# XHSC_HC32F420 register map
Vendor: XHSC Co.Ltd; Series: ARMCM4; File version: 1.2
CPU: CM4 r0p0, little endian, no MPU, no FPU, 3 interrupt priority bits
Registers are 32-bit, read-write, reset 0x0 unless marked. A register's access mark holds for its fields unless they carry their own. Offsets are from the block's base; [hi:lo] are bit positions; {n}, {i} and the like mark numbered series.

## CTRIM
Base 0x40008000
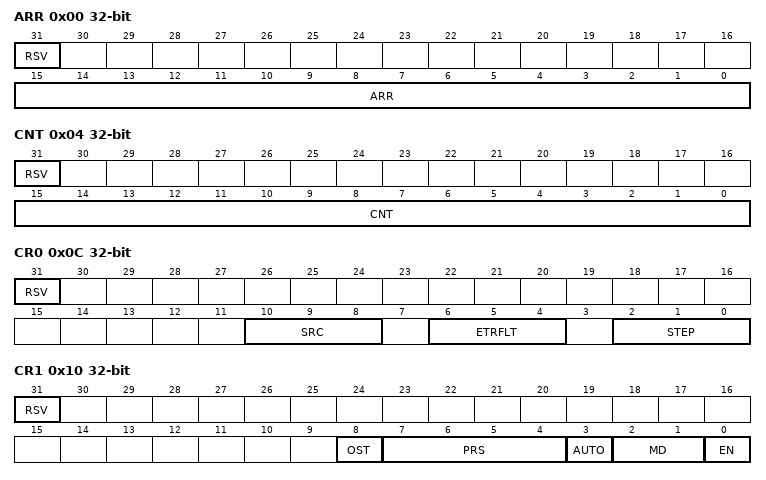
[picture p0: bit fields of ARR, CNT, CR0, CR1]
0x00 ARR (reset mask 0xFFFF)
  [31] RSV, [15:0] ARR
0x04 CNT ro (reset mask 0xFFFF)
  [31] RSV rw, [15:0] CNT rw
0x0C CR0 (reset mask 0xFFFF)
  [31] RSV, [10:8] SRC, [6:4] ETRFLT, [2:0] STEP
0x10 CR1 (reset mask 0xFFFF)
  [31] RSV, [8] OST, [7:4] PRS, [3] AUTO, [2:1] MD, [0] EN
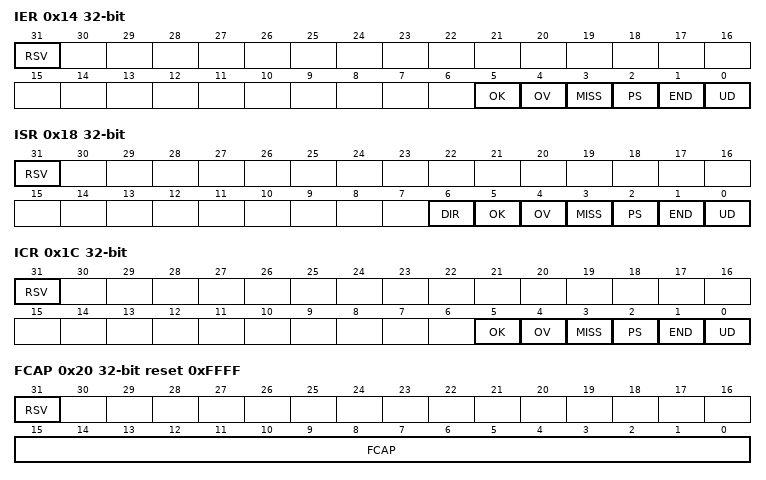
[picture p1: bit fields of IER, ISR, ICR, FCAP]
0x14 IER (reset mask 0xFF)
  [31] RSV, [5] OK, [4] OV, [3] MISS, [2] PS, [1] END, [0] UD
0x18 ISR ro (reset mask 0xFF)
  [31] RSV, [6] DIR, [5] OK, [4] OV, [3] MISS, [2] PS, [1] END, [0] UD
0x1C ICR (reset mask 0xFF)
  [31] RSV, [5] OK, [4] OV, [3] MISS, [2] PS, [1] END, [0] UD
0x20 FCAP ro reset 0xFFFF (reset mask 0xFFFF)
  [31] RSV, [15:0] FCAP
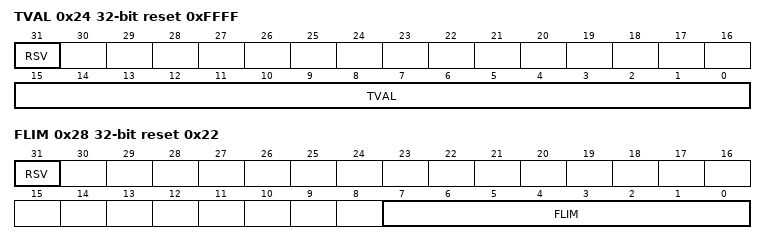
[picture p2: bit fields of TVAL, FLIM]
0x24 TVAL ro reset 0xFFFF (reset mask 0xFFFF)
  [31] RSV, [15:0] TVAL
0x28 FLIM reset 0x22 (reset mask 0xFF)
  [31] RSV, [7:0] FLIM

## DMAC
Base 0x40020000
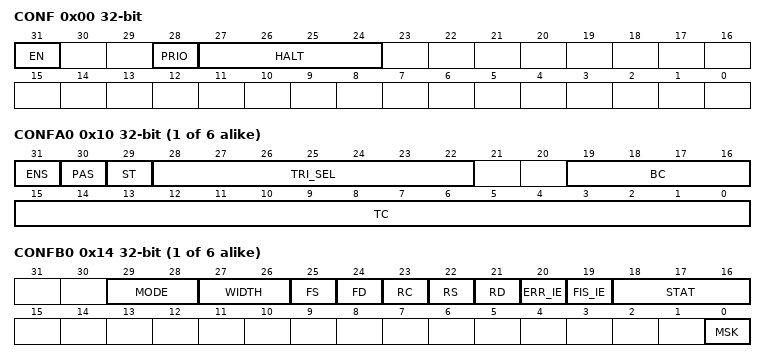
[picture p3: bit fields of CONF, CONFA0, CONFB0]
0x00 CONF
  [31] EN, [28] PRIO, [27:24] HALT
{0x10+0x10*i} CONFA{i} (reset mask 0xFF8FFFFF) (i=0..5)
  [31] ENS, [30] PAS, [29] ST, [28:22] TRI_SEL, [19:16] BC, [15:0] TC
{0x14+0x10*i} CONFB{i} (i=0..5)
  [29:28] MODE, [27:26] WIDTH, [25] FS, [24] FD, [23] RC, [22] RS, [21] RD, [20] ERR_IE, [19] FIS_IE, [18:16] STAT, [0] MSK
{0x18+0x10*i} SRCADR{i} (i=0..5)
  [31:0] SRCADR
{0x1C+0x10*i} DSTADR{i} (i=0..5)
  [31:0] DSTADR

## FLASH
Base 0x40021400
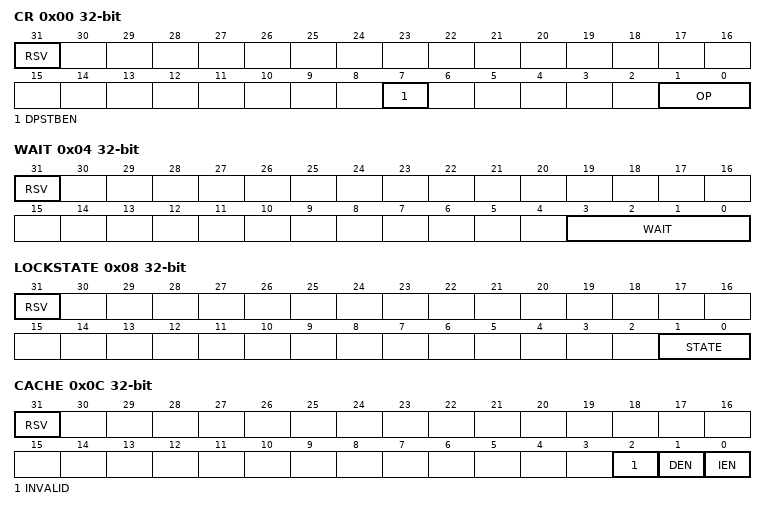
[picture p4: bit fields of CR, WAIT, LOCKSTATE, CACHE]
0x00 CR
  [31] RSV, [7] DPSTBEN, [1:0] OP
0x04 WAIT
  [31] RSV, [3:0] WAIT
0x08 LOCKSTATE ro
  [31] RSV rw, [1:0] STATE rw
0x0C CACHE
  [31] RSV, [2] INVALID, [1] DEN, [0] IEN
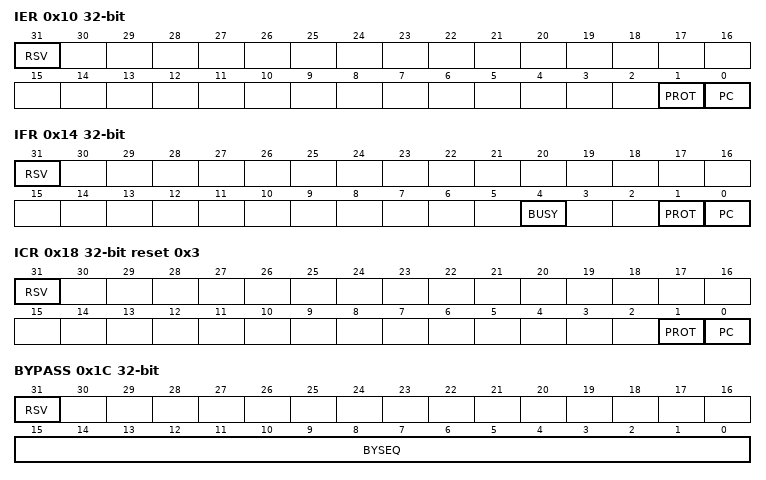
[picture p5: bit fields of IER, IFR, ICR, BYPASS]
0x10 IER (reset mask 0xFF)
  [31] RSV ro, [1] PROT, [0] PC
0x14 IFR (reset mask 0xFF)
  [31] RSV, [4] BUSY ro, [1] PROT ro, [0] PC ro
0x18 ICR reset 0x3
  [31] RSV, [1] PROT, [0] PC
0x1C BYPASS (reset mask 0xFFFF)
  [31] RSV, [15:0] BYSEQ
0x30 SLOCK0
  [31:0] SLOCK
0x34 SLOCK1
  [31:0] SLOCK

## GPIOA — desc GPIO
Base 0x40024000
Same registers: GPIOB 0x40024400, GPIOC 0x40024800, GPIOD 0x40024C00
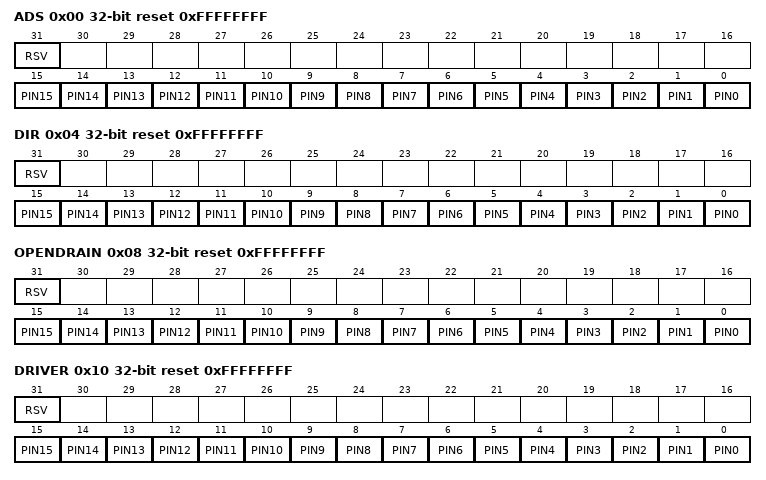
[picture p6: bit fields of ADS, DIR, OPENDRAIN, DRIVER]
0x00 ADS reset 0xFFFFFFFF (reset mask 0xFFFF)
  [31] RSV, [n] PIN{n} (n=0..15)
0x04 DIR reset 0xFFFFFFFF (reset mask 0xFFFF)
  [31] RSV, [n] PIN{n} (n=0..15)
0x08 OPENDRAIN reset 0xFFFFFFFF (reset mask 0xFFFF)
  [31] RSV, [n] PIN{n} (n=0..15)
0x10 DRIVER reset 0xFFFFFFFF (reset mask 0xFFFF)
  [31] RSV, [n] PIN{n} (n=0..15)
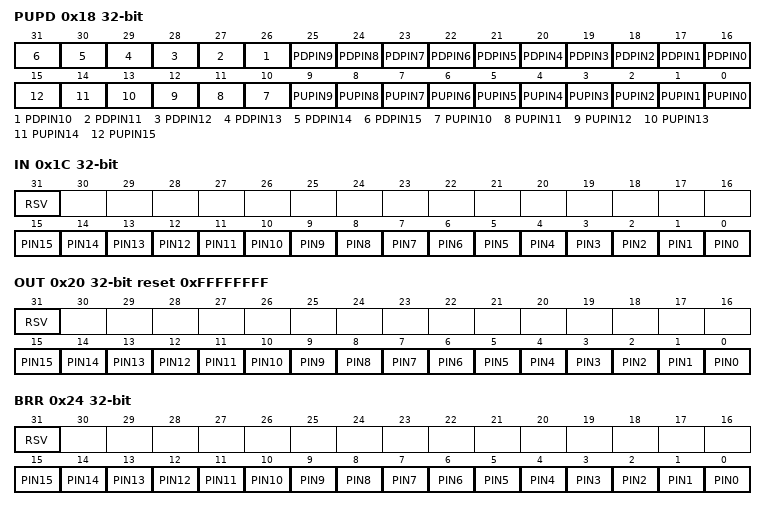
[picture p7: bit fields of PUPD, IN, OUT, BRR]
0x18 PUPD
  [n+16] PDPIN{n} (n=0..15), [n] PUPIN{n} (n=0..15)
0x1C IN ro (reset mask 0xFFFF)
  [31] RSV, [n] PIN{n} (n=0..15)
0x20 OUT reset 0xFFFFFFFF (reset mask 0xFFFF)
  [31] RSV, [n] PIN{n} (n=0..15)
0x24 BRR wo (reset mask 0xFFFF)
  [31] RSV, [n] PIN{n} (n=0..15)
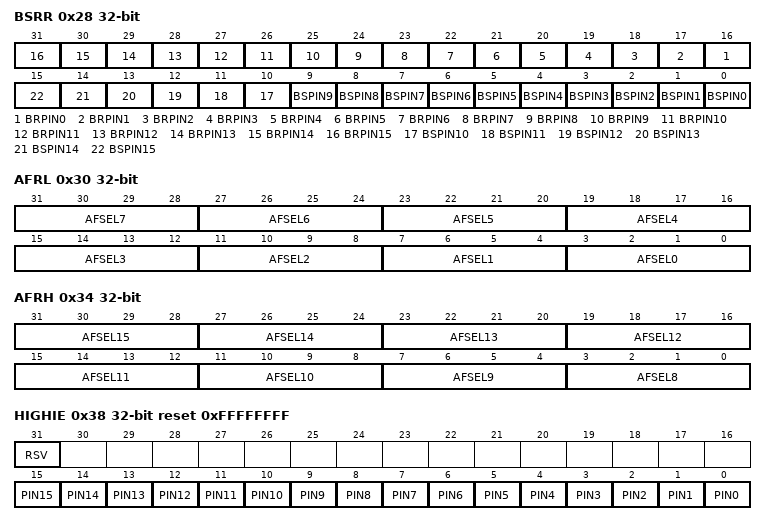
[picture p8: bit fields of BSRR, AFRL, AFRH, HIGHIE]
0x28 BSRR wo
  [n+16] BRPIN{n} (n=0..15), [n] BSPIN{n} (n=0..15)
0x30 AFRL
  [4n+3:4n] AFSEL{n} (n=0..7)
0x34 AFRH
  [4n-29:4n-32] AFSEL{n} (n=8..15)
0x38 HIGHIE reset 0xFFFFFFFF (reset mask 0xFFFF)
  [31] RSV, [n] PIN{n} (n=0..15)
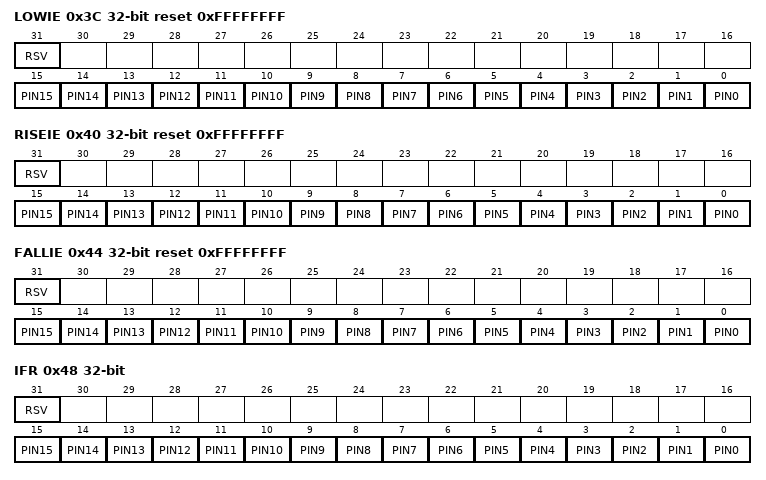
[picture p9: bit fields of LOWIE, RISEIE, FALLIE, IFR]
0x3C LOWIE reset 0xFFFFFFFF (reset mask 0xFFFF)
  [31] RSV, [n] PIN{n} (n=0..15)
0x40 RISEIE reset 0xFFFFFFFF (reset mask 0xFFFF)
  [31] RSV, [n] PIN{n} (n=0..15)
0x44 FALLIE reset 0xFFFFFFFF (reset mask 0xFFFF)
  [31] RSV, [n] PIN{n} (n=0..15)
0x48 IFR ro (reset mask 0xFFFF)
  [31] RSV, [n] PIN{n} (n=0..15)
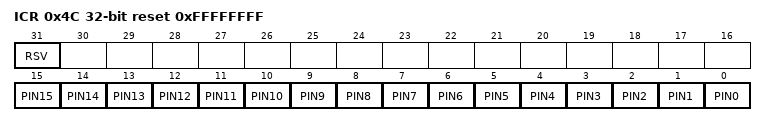
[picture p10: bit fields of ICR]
0x4C ICR reset 0xFFFFFFFF (reset mask 0xFFFF)
  [31] RSV, [n] PIN{n} (n=0..15)

## GPIOAUX
Base 0x4000B800
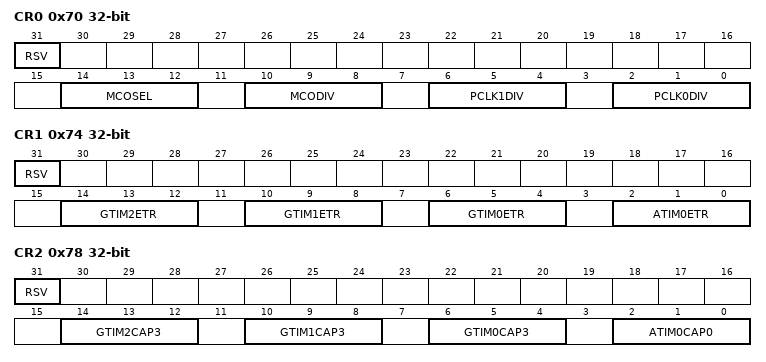
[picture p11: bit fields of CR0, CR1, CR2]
0x70 CR0 (reset mask 0xF)
  [31] RSV, [14:12] MCOSEL, [10:8] MCODIV, [6:4] PCLK1DIV, [2:0] PCLK0DIV
0x74 CR1 (reset mask 0xF)
  [31] RSV, [14:12] GTIM2ETR, [10:8] GTIM1ETR, [6:4] GTIM0ETR, [2:0] ATIM0ETR
0x78 CR2 (reset mask 0xF)
  [31] RSV, [14:12] GTIM2CAP3, [10:8] GTIM1CAP3, [6:4] GTIM0CAP3, [2:0] ATIM0CAP0

## GTIM0 — desc GTIM
Base 0x40005000; alternate view of BTIM0
Same registers: GTIM1 0x40005400 (alternate view of BTIM3), GTIM2 0x40005800 (alternate view of BTIM6)
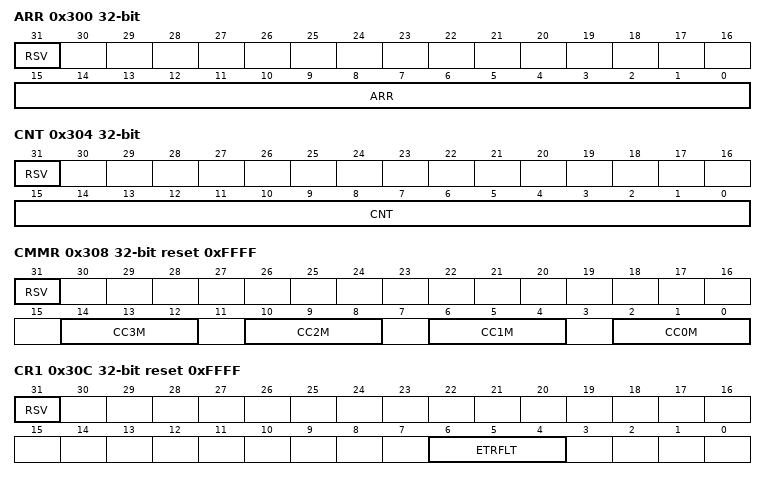
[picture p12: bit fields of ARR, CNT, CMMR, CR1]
0x300 ARR (reset mask 0xFFFF)
  [31] RSV, [15:0] ARR
0x304 CNT (reset mask 0xFFFF)
  [31] RSV, [15:0] CNT
0x308 CMMR reset 0xFFFF (reset mask 0xFFFF)
  [31] RSV, [4n+2:4n] CC{n}M (n=0..3)
0x30C CR1 reset 0xFFFF (reset mask 0xFFFF)
  [31] RSV, [6:4] ETRFLT
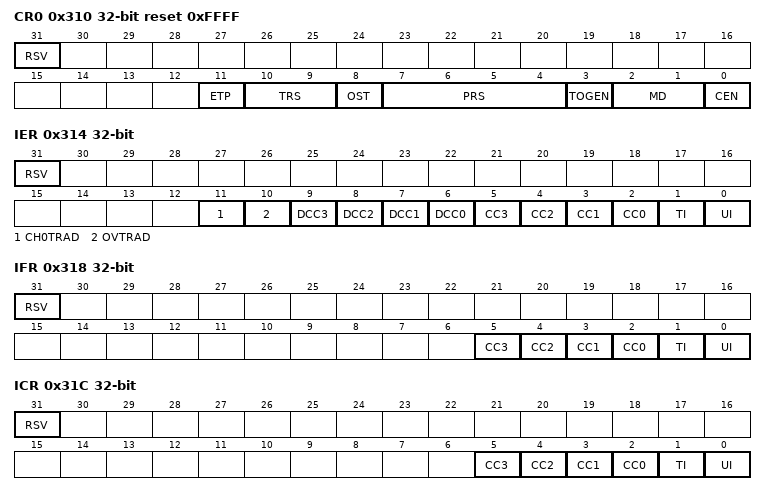
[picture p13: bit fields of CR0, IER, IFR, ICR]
0x310 CR0 reset 0xFFFF (reset mask 0xFFFF)
  [31] RSV, [11] ETP, [10:9] TRS, [8] OST, [7:4] PRS, [3] TOGEN, [2:1] MD, [0] CEN
0x314 IER (reset mask 0xF)
  [31] RSV, [11] CH0TRAD, [10] OVTRAD, [n+6] DCC{n} (n=0..3), [n+2] CC{n} (n=0..3), [1] TI, [0] UI
0x318 IFR (reset mask 0xF)
  [31] RSV, [n+2] CC{n} (n=0..3), [1] TI, [0] UI
0x31C ICR (reset mask 0xF)
  [31] RSV, [n+2] CC{n} (n=0..3), [1] TI, [0] UI
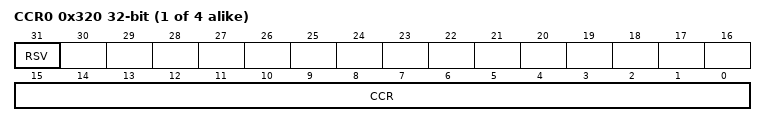
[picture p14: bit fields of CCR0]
{0x320+4i} CCR{i} (reset mask 0xFFFF) (i=0..3)
  [31] RSV, [15:0] CCR
